VERSION ""

NS_ :

BS_:

BU_: Lenkmotor NJX Third_Party VCU

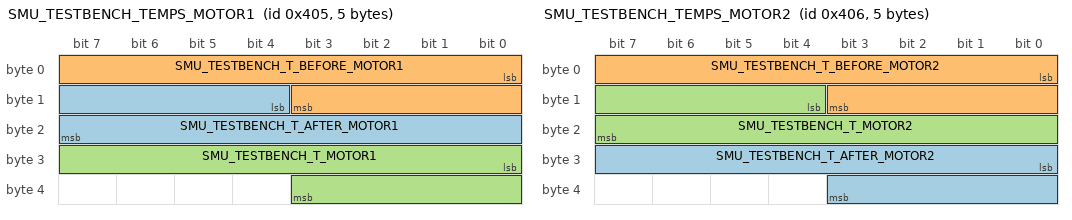
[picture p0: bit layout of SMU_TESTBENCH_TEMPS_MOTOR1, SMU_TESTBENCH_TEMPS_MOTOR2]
BO_ 1029 SMU_TESTBENCH_TEMPS_MOTOR1: 5 VCU
 SG_ SMU_TESTBENCH_T_AFTER_MOTOR1  : 12|12@1+ (0.1,0) [0|409.5] "°C" Vector__XXX
 SG_ SMU_TESTBENCH_T_BEFORE_MOTOR1  : 0|12@1+ (0.1,0) [0|409.5] "°C" Vector__XXX
 SG_ SMU_TESTBENCH_T_MOTOR1  : 24|12@1+ (0.1,0) [0|409.5] "°C" Vector__XXX

BO_ 1030 SMU_TESTBENCH_TEMPS_MOTOR2: 5 VCU
 SG_ SMU_TESTBENCH_T_AFTER_MOTOR2  : 24|12@1+ (0.1,0) [0|409.5] "°C" Vector__XXX
 SG_ SMU_TESTBENCH_T_BEFORE_MOTOR2  : 0|12@1+ (0.1,0) [0|409.5] "°C" Vector__XXX
 SG_ SMU_TESTBENCH_T_MOTOR2  : 12|12@1+ (0.1,0) [0|409.5] "°C" Vector__XXX

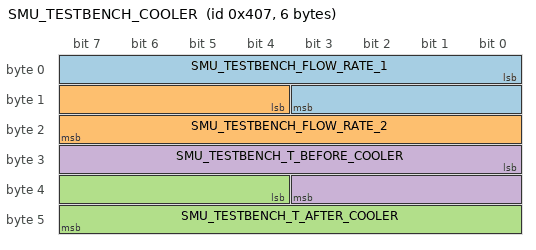
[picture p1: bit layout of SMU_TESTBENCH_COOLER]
BO_ 1031 SMU_TESTBENCH_COOLER: 6 VCU
 SG_ SMU_TESTBENCH_FLOW_RATE_1  : 0|12@1+ (0.1,0) [0|409.5] "l/m" Vector__XXX
 SG_ SMU_TESTBENCH_FLOW_RATE_2  : 12|12@1+ (0.1,0) [0|409.5] "l/m" Vector__XXX
 SG_ SMU_TESTBENCH_T_AFTER_COOLER  : 36|12@1+ (0.1,0) [0|409.5] "°C" Vector__XXX
 SG_ SMU_TESTBENCH_T_BEFORE_COOLER  : 24|12@1+ (0.1,0) [0|409.5] "°C" Vector__XXX

BO_ 1664 CAN_Flash_RX: 8 VCU

BO_ 1675 CAN_Flash_SMU_TESTBENCH_TX: 8 VCU

BA_DEF_  "DBName" STRING ;
BA_DEF_ BO_  "GenMsgCycleTime" INT 0 0;
BA_DEF_ BO_  "GenMsgSendType" ENUM  "Cyclic","OnEvent";
BA_DEF_ SG_  "GenSigSendType" ENUM  "NoSigSendType";
BA_DEF_ SG_  "GenSigStartValue" INT 0 0;
BA_DEF_ SG_  "SPN" INT 0 524287;
BA_DEF_DEF_  "DBName" "";
BA_DEF_DEF_  "GenMsgCycleTime" 0;
BA_DEF_DEF_  "GenMsgSendType" "NoMsgSendType";
BA_DEF_DEF_  "GenSigSendType" "Cyclic";
BA_DEF_DEF_  "SPN" 0;
BA_ "DBName" "CAN1";
BA_ "GenMsgCycleTime" BO_ 1029 100;
BA_ "GenMsgSendType" BO_ 1029 0;
BA_ "GenMsgCycleTime" BO_ 1030 100;
BA_ "GenMsgSendType" BO_ 1030 0;
BA_ "GenMsgCycleTime" BO_ 1031 100;
BA_ "GenMsgSendType" BO_ 1031 0;
BA_ "GenMsgSendType" BO_ 1664 1;
BA_ "GenMsgSendType" BO_ 1675 1;
BA_ "GenSigStartValue" SG_ 1029 SMU_TESTBENCH_T_AFTER_MOTOR1 0;
BA_ "GenSigStartValue" SG_ 1029 SMU_TESTBENCH_T_BEFORE_MOTOR1 0;
BA_ "GenSigStartValue" SG_ 1029 SMU_TESTBENCH_T_MOTOR1 0;
BA_ "GenSigStartValue" SG_ 1030 SMU_TESTBENCH_T_AFTER_MOTOR2 0;
BA_ "GenSigStartValue" SG_ 1030 SMU_TESTBENCH_T_BEFORE_MOTOR2 0;
BA_ "GenSigStartValue" SG_ 1030 SMU_TESTBENCH_T_MOTOR2 0;
BA_ "GenSigStartValue" SG_ 1031 SMU_TESTBENCH_FLOW_RATE_1 0;
BA_ "GenSigStartValue" SG_ 1031 SMU_TESTBENCH_FLOW_RATE_2 0;
BA_ "GenSigStartValue" SG_ 1031 SMU_TESTBENCH_T_AFTER_COOLER 0;
BA_ "GenSigStartValue" SG_ 1031 SMU_TESTBENCH_T_BEFORE_COOLER 0;
SIG_VALTYPE_ 1029 SMU_TESTBENCH_T_AFTER_MOTOR1 : 0;
SIG_VALTYPE_ 1029 SMU_TESTBENCH_T_BEFORE_MOTOR1 : 0;
SIG_VALTYPE_ 1029 SMU_TESTBENCH_T_MOTOR1 : 0;
SIG_VALTYPE_ 1030 SMU_TESTBENCH_T_AFTER_MOTOR2 : 0;
SIG_VALTYPE_ 1030 SMU_TESTBENCH_T_BEFORE_MOTOR2 : 0;
SIG_VALTYPE_ 1030 SMU_TESTBENCH_T_MOTOR2 : 0;
SIG_VALTYPE_ 1031 SMU_TESTBENCH_FLOW_RATE_1 : 0;
SIG_VALTYPE_ 1031 SMU_TESTBENCH_FLOW_RATE_2 : 0;
SIG_VALTYPE_ 1031 SMU_TESTBENCH_T_AFTER_COOLER : 0;
SIG_VALTYPE_ 1031 SMU_TESTBENCH_T_BEFORE_COOLER : 0;
